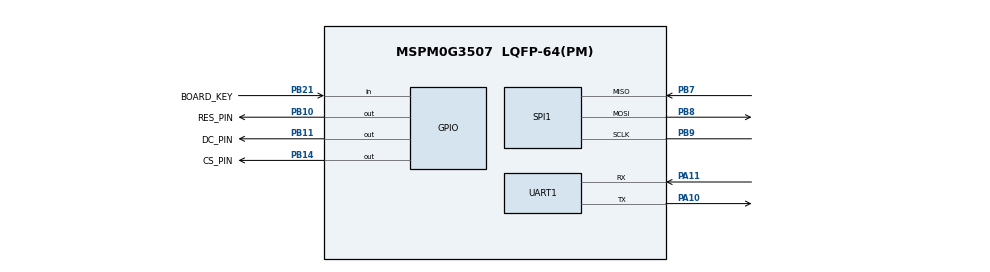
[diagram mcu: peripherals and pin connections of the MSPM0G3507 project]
/**
 * These arguments were used when this file was generated. They will be automatically applied on subsequent loads
 * via the GUI or CLI. Run CLI with '--help' for additional information on how to override these arguments.
 * @cliArgs --device "MSPM0G350X" --part "Default" --package "LQFP-64(PM)" --product "mspm0_sdk@2.10.00.04"
 * @v2CliArgs --device "MSPM0G3507" --package "LQFP-64(PM)" --product "mspm0_sdk@2.10.00.04"
 * @versions {"tool":"1.26.2+4477"}
 */

/**
 * Import the modules used in this configuration.
 */
const GPIO   = scripting.addModule("/ti/driverlib/GPIO", {}, false);
const GPIO1  = GPIO.addInstance();
const GPIO2  = GPIO.addInstance();
const GPIO3  = GPIO.addInstance();
const I2C    = scripting.addModule("/ti/driverlib/I2C", {}, false);
const I2C1   = I2C.addInstance();
const SPI    = scripting.addModule("/ti/driverlib/SPI", {}, false);
const SPI1   = SPI.addInstance();
const SYSCTL = scripting.addModule("/ti/driverlib/SYSCTL");
const TIMER  = scripting.addModule("/ti/driverlib/TIMER", {}, false);
const TIMER1 = TIMER.addInstance();
const UART   = scripting.addModule("/ti/driverlib/UART", {}, false);
const UART1  = UART.addInstance();

/**
 * Write custom configuration values to the imported modules.
 */
const gate7  = system.clockTree["MFCLKGATE"];
gate7.enable = true;

GPIO1.$name                         = "LED1";
GPIO1.port                          = "PORTB";
GPIO1.associatedPins[0].$name       = "PIN_22";
GPIO1.associatedPins[0].assignedPin = "22";

const Board = scripting.addModule("/ti/driverlib/Board", {}, false);

GPIO2.$name                         = "SPI_OLED_PIN";
GPIO2.port                          = "PORTB";
GPIO2.associatedPins.create(3);
GPIO2.associatedPins[0].$name       = "RES_PIN";
GPIO2.associatedPins[0].assignedPin = "10";
GPIO2.associatedPins[0].ioStructure = "SD";
GPIO2.associatedPins[0].pin.$assign = "PB10";
GPIO2.associatedPins[1].ioStructure = "SD";
GPIO2.associatedPins[1].$name       = "DC_PIN";
GPIO2.associatedPins[1].assignedPin = "11";
GPIO2.associatedPins[1].pin.$assign = "PB11";
GPIO2.associatedPins[2].$name       = "CS_PIN";
GPIO2.associatedPins[2].assignedPin = "14";
GPIO2.associatedPins[2].ioStructure = "SD";
GPIO2.associatedPins[2].pin.$assign = "PB14";

GPIO3.$name                              = "KEY_GROIP";
GPIO3.associatedPins[0].$name            = "BOARD_KEY";
GPIO3.associatedPins[0].direction        = "INPUT";
GPIO3.associatedPins[0].assignedPort     = "PORTB";
GPIO3.associatedPins[0].assignedPin      = "21";
GPIO3.associatedPins[0].internalResistor = "PULL_UP";
GPIO3.associatedPins[0].pin.$assign      = "PB21";

I2C1.$name              = "I2C_0";
I2C1.sdaPinConfig.$name = "ti_driverlib_gpio_GPIOPinGeneric5";
I2C1.sclPinConfig.$name = "ti_driverlib_gpio_GPIOPinGeneric6";

SPI1.$name                              = "SPI";
SPI1.frameFormat                        = "MOTO3";
SPI1.sclkPinConfig.direction            = scripting.forceWrite("OUTPUT");
SPI1.sclkPinConfig.onlyInternalResistor = scripting.forceWrite(false);
SPI1.sclkPinConfig.passedPeripheralType = scripting.forceWrite("Digital");
SPI1.sclkPinConfig.$name                = "ti_driverlib_gpio_GPIOPinGeneric2";
SPI1.mosiPinConfig.direction            = scripting.forceWrite("OUTPUT");
SPI1.mosiPinConfig.hideOutputInversion  = scripting.forceWrite(false);
SPI1.mosiPinConfig.onlyInternalResistor = scripting.forceWrite(false);
SPI1.mosiPinConfig.passedPeripheralType = scripting.forceWrite("Digital");
SPI1.mosiPinConfig.$name                = "ti_driverlib_gpio_GPIOPinGeneric3";
SPI1.misoPinConfig.onlyInternalResistor = scripting.forceWrite(false);
SPI1.misoPinConfig.passedPeripheralType = scripting.forceWrite("Digital");
SPI1.misoPinConfig.$name                = "ti_driverlib_gpio_GPIOPinGeneric4";
SPI1.peripheral.sclkPin.$assign         = "PB9";
SPI1.peripheral.mosiPin.$assign         = "PB8";
SPI1.peripheral.misoPin.$assign         = "PB7";

SYSCTL.forceDefaultClkConfig = true;
SYSCTL.clockTreeEn           = true;

TIMER1.$name              = "TIMER_0";
TIMER1.timerClkPrescale   = 100;
TIMER1.timerMode          = "PERIODIC";
TIMER1.timerClkDiv        = 8;
TIMER1.timerStartTimer    = true;
TIMER1.interrupts         = ["ZERO"];
TIMER1.timerPeriod        = "1ms";
TIMER1.peripheral.$assign = "TIMA0";

UART1.$name                    = "UART_0";
UART1.targetBaudRate           = 115200;
UART1.uartClkSrc               = "MFCLK";
UART1.enabledInterrupts        = ["RX"];
UART1.peripheral.$assign       = "UART0";
UART1.peripheral.rxPin.$assign = "PA11";
UART1.peripheral.txPin.$assign = "PA10";
UART1.txPinConfig.$name        = "ti_driverlib_gpio_GPIOPinGeneric0";
UART1.rxPinConfig.$name        = "ti_driverlib_gpio_GPIOPinGeneric1";

/**
 * Pinmux solution for unlocked pins/peripherals. This ensures that minor changes to the automatic solver in a future
 * version of the tool will not impact the pinmux you originally saw.  These lines can be completely deleted in order to
 * re-solve from scratch.
 */
GPIO1.associatedPins[0].pin.$suggestSolution = "PB22";
Board.peripheral.$suggestSolution            = "DEBUGSS";
Board.peripheral.swclkPin.$suggestSolution   = "PA20";
Board.peripheral.swdioPin.$suggestSolution   = "PA19";
I2C1.peripheral.$suggestSolution             = "I2C0";
I2C1.peripheral.sdaPin.$suggestSolution      = "PA0";
I2C1.peripheral.sclPin.$suggestSolution      = "PA1";
SPI1.peripheral.$suggestSolution             = "SPI1";
